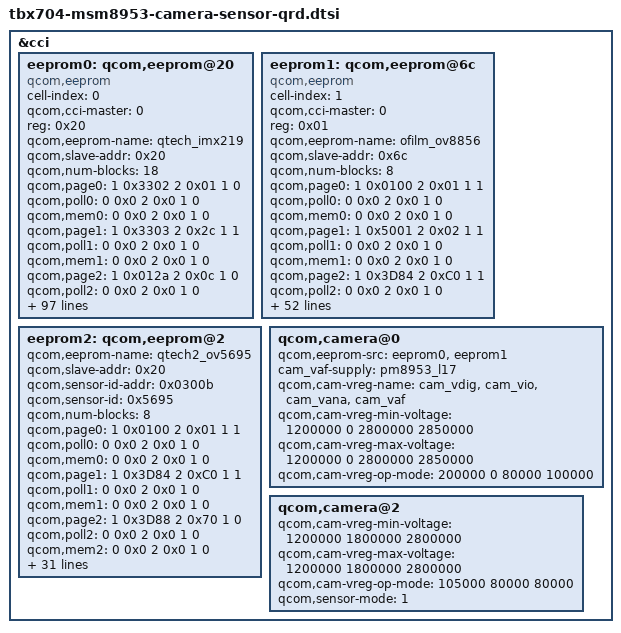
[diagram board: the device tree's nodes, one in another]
/*
 * Copyright (c) 2015-2016, The Linux Foundation. All rights reserved.
 *
 * This program is free software; you can redistribute it and/or modify
 * it under the terms of the GNU General Public License version 2 and
 * only version 2 as published by the Free Software Foundation.
 *
 * This program is distributed in the hope that it will be useful,
 * but WITHOUT ANY WARRANTY; without even the implied warranty of
 * MERCHANTABILITY or FITNESS FOR A PARTICULAR PURPOSE.  See the
 * GNU General Public License for more details.
 */

&cci {
	/delete-node/ qcom,eeprom@0;
	eeprom0: qcom,eeprom@20 {
		cell-index = <0>;
		compatible = "qcom,eeprom";
		qcom,cci-master = <0>;
		reg = <0x20>;
         

// add  cuirui  start
		qcom,eeprom-name = "qtech_imx219"; //add
		qcom,slave-addr = <0x20>;          //add accoring to the camera addres
		qcom,num-blocks = <18>;
		qcom,page0 = <1 0x3302 2 0x01 1 0>;
		qcom,poll0 = <0 0x0 2 0x0 1 0>;
		qcom,mem0  = <0 0x0 2 0x0 1 0>;

		qcom,page1 = <1 0x3303 2 0x2c 1 1>;
		qcom,poll1 = <0 0x0 2 0x0 1 0>;
		qcom,mem1  = <0 0x0 2 0x0 1 0>;

		qcom,page2 = <1 0x012a 2 0x0c 1 0>;
		qcom,poll2 = <0 0x0 2 0x0 1 0>;
		qcom,mem2  = <0 0x0 2 0x0 1 0>;

		qcom,page3 = <1 0x012b 2 0x00 1 0>;
		qcom,poll3 = <0 0x0 2 0x0 1 0>;
		qcom,mem3  = <0 0x0 2 0x0 1 0>;

		qcom,page4 = <1 0x3300 2 0x08 1 0>;
		qcom,poll4 = <0 0x0 2 0x0 1 0>;
		qcom,mem4  = <0 0x0 2 0x0 1 0>;

		qcom,page5 = <1 0x3200 2 0x01 1 5>;
		qcom,poll5 = <0 0x0 2 0x0 1 0>;
		qcom,mem5  = <0 0x0 2 0x0 1 0>;

		qcom,page6 = <1 0x3202 2 0x00 1 0>;
		qcom,poll6 = <0 0x0 2 0x0 1 0>;
		qcom,mem6  = <64 0x3204 2 0x0 1 0>;

		qcom,page7 = <1 0x3202 2 0x01 1 0>;
		qcom,poll7 = <0 0x0 2 0x0 1 0>;
		qcom,mem7  = <64 0x3204 2 0x0 1 0>;

		qcom,page8 = <1 0x3300 2 0x00 1 0>;
		qcom,poll8 = <0 0x0 2 0x0 1 0>;
		qcom,mem8  = <0 0x3204 2 0x0 1 0>;

		qcom,page9 = <1 0x3202 2 0x02 1 0>;
		qcom,poll9 = <0 0x0 2 0x0 1 0>;
		qcom,mem9  = <64 0x3204 2 0x0 1 0>;

		qcom,page10 = <1 0x3202 2 0x03 1 0>;
		qcom,poll10 = <0 0x0 2 0x0 1 0>;
		qcom,mem10  = <64 0x3204 2 0x0 1 0>;

		qcom,page11 = <1 0x3202 2 0x04 1 0>;
		qcom,poll11 = <0 0x0 2 0x0 1 0>;
		qcom,mem11  = <64 0x3204 2 0x0 1 0>;

		qcom,page12 = <1 0x3202 2 0x05 1 0>;
		qcom,poll12 = <0 0x0 2 0x0 1 0>;
		qcom,mem12  = <64 0x3204 2 0x0 1 0>;

		qcom,page13 = <1 0x3202 2 0x06 1 0>;
		qcom,poll13 = <0 0x0 2 0x0 1 0>;
		qcom,mem13  = <64 0x3204 2 0x0 1 0>;

		qcom,page14 = <1 0x3202 2 0x07 1 0>;
		qcom,poll14 = <0 0x0 2 0x0 1 0>;
		qcom,mem14  = <64 0x3204 2 0x0 1 0>;

		qcom,page15 = <1 0x3202 2 0x08 1 0>;
		qcom,poll15 = <0 0x0 2 0x0 1 0>;
		qcom,mem15  = <64 0x3204 2 0x0 1 0>;

		qcom,page16 = <1 0x3202 2 0x09 1 0>;
		qcom,poll16 = <0 0x0 2 0x0 1 0>;
		qcom,mem16  = <64 0x3204 2 0x0 1 0>;

		qcom,page17 = <1 0x3202 2 0x0a 1 0>;
		qcom,poll17 = <0 0x0 2 0x0 1 0>;
		qcom,mem17  = <64 0x3204 2 0x0 1 0>;

		qcom,page18 = <1 0x0190 2 0x01 1 0>;
		qcom,poll18 = <0 0x0 2 0x0 1 0>;
		qcom,mem18  = <0 0x3204 2 0x0 1 0>;

		qcom,page19 = <1 0x0192 2 0x00 1 0>;
		qcom,poll19 = <0 0x0 2 0x0 1 0>;
		qcom,mem19  = <0 0x3204 2 0x0 1 0>;

		qcom,page20 = <1 0x0191 2 0x00 1 0>;
		qcom,poll20 = <0 0x0 2 0x0 1 0>;
		qcom,mem20  = <0 0x3204 2 0x0 1 0>;

		qcom,page21 = <1 0x0193 2 0x00 1 0>;
		qcom,poll21 = <0 0x0 2 0x0 1 0>;
		qcom,mem21  = <0 0x3204 2 0x0 1 0>;

		qcom,page22 = <1 0x01A4 2 0x03 1 0>;
		qcom,poll22 = <0 0x0 2 0x0 1 0>;
		qcom,mem22  = <0 0x3204 2 0x0 1 0>;

		cam_vio-supply = <&pm8953_l6>;
		cam_vdig-supply = <&pm8953_l2>;
		cam_vana-supply = <&pm8953_l22>;
		cam_vaf-supply = <&pm8953_l17>;
		qcom,cam-vreg-name = "cam_vio", "cam_vdig", "cam_vana","cam_vaf";
		qcom,cam-vreg-min-voltage = <0 1100000 2800000 2850000>;
		qcom,cam-vreg-max-voltage = <0 1100000 2800000 2850000>;
		qcom,cam-vreg-op-mode = <0 105000 80000 100000>;
		pinctrl-names = "cam_default", "cam_suspend";
		pinctrl-0 = <&cam_sensor_mclk0_default
						&cam_sensor_rear_default>;
		pinctrl-1 = <&cam_sensor_mclk0_sleep &cam_sensor_rear_sleep>;
		gpios = <&tlmm 26 0>,
			<&tlmm 40 0>,
			<&tlmm 39 0>;
		qcom,gpio-reset = <1>;
		qcom,gpio-standby = <2>;
		qcom,gpio-req-tbl-num = <0 1 2>;
		qcom,gpio-req-tbl-flags = <1 0 0>;
		qcom,gpio-req-tbl-label = "CAMIF_MCLK0",
			"CAM_RESET0",
			"CAM_STANDBY0";

		qcom,cam-power-seq-type = "sensor_vreg","sensor_vreg","sensor_vreg","sensor_clk",
					"sensor_gpio","sensor_gpio","sensor_gpio","sensor_gpio";
		qcom,cam-power-seq-val = "cam_vdig","cam_vana","cam_vio","sensor_cam_mclk","sensor_gpio_reset",
					"sensor_gpio_reset","sensor_gpio_standby","sensor_gpio_standby";
		qcom,cam-power-seq-cfg-val = <0 0 0 24000000 0 1 0 1>;
		qcom,cam-power-seq-delay = <0 0 0 1 1 1 1 10>;
		status = "ok";
		clocks = <&clock_gcc clk_mclk0_clk_src>,
				<&clock_gcc clk_gcc_camss_mclk0_clk>;
		clock-names = "cam_src_clk", "cam_clk";
		qcom,clock-rates = <19200000 0>;
	};

      eeprom1: qcom,eeprom@6c{
                   cell-index = <1>;
                   compatible = "qcom,eeprom";
                   qcom,cci-master = <0>;
                   reg = <0x01>;
   //add  jack  start
                   qcom,eeprom-name = "ofilm_ov8856"; //add
                   qcom,slave-addr = <0x6c>;          //add accoring to the camera address                                            
                   qcom,num-blocks = <8>;             //add
 
                   qcom,page0 = <1 0x0100 2 0x01 1 1>;//add, write
                   qcom,poll0 = <0 0x0 2 0x0 1 0>;
                   qcom,mem0  = <0 0x0 2 0x0 1 0>;//read
                   
                   qcom,page1 = <1 0x5001 2 0x02 1 1>;//modify
                   qcom,poll1 = <0 0x0 2 0x0 1 0>;
                   qcom,mem1  = <0 0x0 2 0x0 1 0>;
 
                   qcom,page2 = <1 0x3D84 2 0xC0 1 1>;//modify
		   qcom,poll2 = <0 0x0 2 0x0 1 0>;
		   qcom,mem2  = <0 0x0 2 0x0 1 0>;

		   qcom,page3 = <1 0x3D88 2 0x70 1 0>;
		   qcom,poll3 = <0 0x0 2 0x0 1 0>;
		   qcom,mem3  = <0 0x0 2 0x0 1 0>;

		   qcom,page4 = <1 0x3d89 2 0x10 1 0>;
		   qcom,poll4 = <0 0x0 2 0x0 1 0>;
		   qcom,mem4  = <0 0x0 2 0x0 1 0>;

		   qcom,page5 = <1 0x3d8A 2 0x72 1 0>;
		   qcom,poll5 = <0 0x0 2 0x0 1 0>;
		   qcom,mem5  = <0 0x0 2 0x0 1 0>;

		   qcom,page6 = <1 0x3D8B 2 0x0d 1 0>;
		   qcom,poll6 = <0 0x0 2 0x0 1 0>;
		   qcom,mem6 =  <0 0x0 2 0x0 1 0>;
         
                   qcom,page7 = <1 0x3D81 2 0x01 1 10>;
		   qcom,poll7 = <0 0x0 2 0x0 1 0>;
		   qcom,mem7  = <510 0x7010 2 0x0 1 0>;
 
                 cam_vio-supply = <&pm8953_l6>;
                 cam_vdig-supply = <&pm8953_l2>;
                 cam_vana-supply = <&pm8953_l22>;
                 cam_vaf-supply = <&pm8953_l17>;
                 qcom,cam-vreg-name = "cam_vio", "cam_vdig", "cam_vana","cam_vaf";
                 qcom,cam-vreg-min-voltage = <0 1100000 2800000 2850000>;
                 qcom,cam-vreg-max-voltage = <0 1100000 2800000 2850000>;
                 qcom,cam-vreg-op-mode = <0 105000 80000 100000>;
                 pinctrl-names = "cam_default", "cam_suspend";
                 pinctrl-0 = <&cam_sensor_mclk0_default
                                                 &cam_sensor_rear_default>;
                 pinctrl-1 = <&cam_sensor_mclk0_sleep &cam_sensor_rear_sleep>;
                 gpios = <&tlmm 26 0>,
                         <&tlmm 40 0>,
                         <&tlmm 39 0>;
                 qcom,gpio-reset = <1>;
                 qcom,gpio-standby = <2>;
                 qcom,gpio-req-tbl-num = <0 1 2>;
                 qcom,gpio-req-tbl-flags = <1 0 0>;
                 qcom,gpio-req-tbl-label = "CAMIF_MCLK0",
                         "CAM_RESET0",
                         "CAM_STANDBY0";
                 qcom,cam-power-seq-type = "sensor_vreg","sensor_vreg","sensor_vreg","sensor_clk",
                                        "sensor_gpio","sensor_gpio","sensor_gpio","sensor_gpio";
                 qcom,cam-power-seq-val = "cam_vdig","cam_vana","cam_vio","sensor_cam_mclk","sensor_gpio_reset",
                                         "sensor_gpio_reset","sensor_gpio_standby","sensor_gpio_standby";
                 qcom,cam-power-seq-cfg-val = <0 0 0 24000000 0 1 0 1>;
                 qcom,cam-power-seq-delay = <0 0 0 1 1 1 1 10>;
                 status = "ok";
                 clocks = <&clock_gcc clk_mclk0_clk_src>,
                                 <&clock_gcc clk_gcc_camss_mclk0_clk>;
                 clock-names = "cam_src_clk", "cam_clk";
                 qcom,clock-rates = <19200000 0>;

          };

	eeprom2: qcom,eeprom@2 {
//add  jack  start
		qcom,eeprom-name = "qtech2_ov5695"; //add
		qcom,slave-addr = <0x20>;          //add accoring to the camera address
		qcom,sensor-id-addr = <0x0300b>;
		qcom,sensor-id = <0x5695>;
		qcom,num-blocks = <8>;             //add

		qcom,page0 = <1 0x0100 2 0x01 1 1>;//add
		qcom,poll0 = <0 0x0 2 0x0 1 0>;
		qcom,mem0  = <0 0x0 2 0x0 1 0>;

		qcom,page1 = <1 0x3D84 2 0xC0 1 1>;//modify
		qcom,poll1 = <0 0x0 2 0x0 1 0>;
		qcom,mem1  = <0 0x0 2 0x0 1 0>;

		qcom,page2 = <1 0x3D88 2 0x70 1 0>;
		qcom,poll2 = <0 0x0 2 0x0 1 0>;
		qcom,mem2  = <0 0x0 2 0x0 1 0>;

		qcom,page3 = <1 0x3d89 2 0x0c 1 0>;
		qcom,poll3 = <0 0x0 2 0x0 1 0>;
		qcom,mem3  = <0 0x0 2 0x0 1 0>;

		qcom,page4 = <1 0x3d8A 2 0x70 1 0>;
		qcom,poll4 = <0 0x0 2 0x0 1 0>;
		qcom,mem4  = <0 0x0 2 0x0 1 0>;

		qcom,page5 = <1 0x3D8B 2 0x1A 1 0>;
		qcom,poll5 = <0 0x0 2 0x0 1 0>;
		qcom,mem5 =  <0 0x0 2 0x0 1 0>;

		qcom,page6 = <16 0x700c 2 0x00 1 0>;
		qcom,poll6 = <0 0x0 2 0x0 1 0>;
		qcom,mem6 =  <0 0x0 2 0x0 1 0>;

		qcom,page7 = <1 0x3d81 2 0x01 1 10>;
		qcom,poll7 = <0 0x0 2 0x0 1 0>;
		qcom,mem7  = <16 0x700C 2 0x0 1 0>;
    //add  jack end
		qcom,cam-vreg-min-voltage = <1200000 1800000 2800000>;
		qcom,cam-vreg-max-voltage = <1200000 1800000 2800000>;
		qcom,cam-vreg-op-mode = <105000 80000 80000>;

		qcom,cam-power-seq-type = "sensor_gpio", "sensor_gpio", "sensor_vreg",
			"sensor_vreg", "sensor_vreg", "sensor_clk" , "sensor_gpio", "sensor_gpio";//zhang
		qcom,cam-power-seq-val = "sensor_gpio_reset", "sensor_gpio_standby", "cam_vana",
			"cam_vdig",	"cam_vio", "sensor_cam_mclk", "sensor_gpio_reset", "sensor_gpio_standby";  //zhang
		qcom,cam-power-seq-cfg-val = <0 0 1 1 1 24000000 1 1>;    //zhang
		qcom,cam-power-seq-delay = <1 1 0 0 0 1 1 1>;    //zhang
		/delete-property/ qcom,sensor-mode;
	};


	qcom,camera@0 {
		qcom,eeprom-src = <&eeprom0 &eeprom1>;
		cam_vaf-supply = <&pm8953_l17>;
		qcom,cam-vreg-name = "cam_vdig", "cam_vio", "cam_vana","cam_vaf";
		qcom,cam-vreg-min-voltage = <1200000 0 2800000 2850000>;
		qcom,cam-vreg-max-voltage = <1200000 0 2800000 2850000>;
		qcom,cam-vreg-op-mode = <200000 0 80000 100000>;
	};
	/delete-node/ qcom,camera@1;
	qcom,camera@2 {
		qcom,cam-vreg-min-voltage = <1200000 1800000 2800000>;
		qcom,cam-vreg-max-voltage = <1200000 1800000 2800000>;
		qcom,cam-vreg-op-mode = <105000 80000 80000>;
		qcom,sensor-mode = <1>;
	};
};
